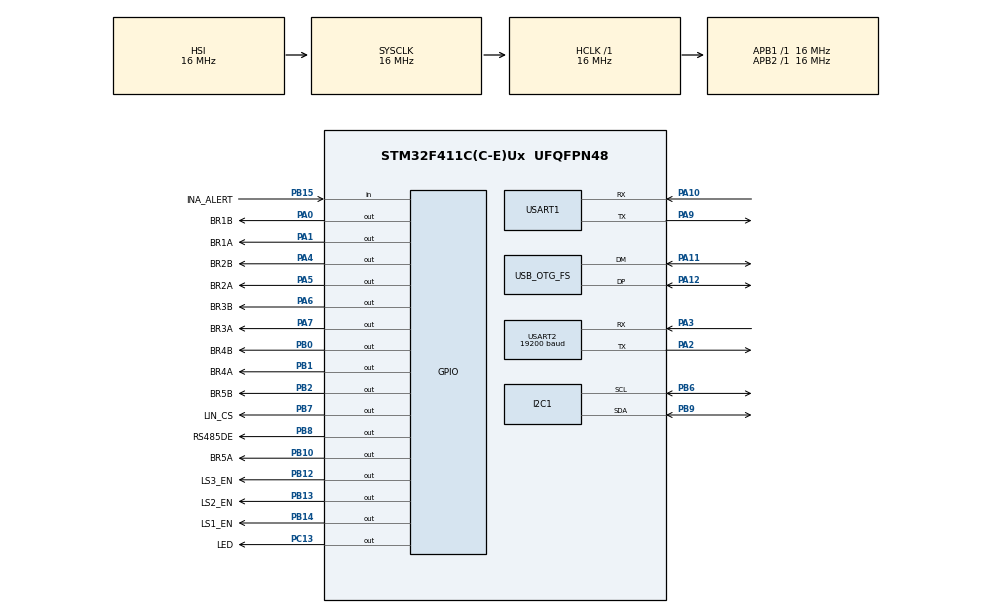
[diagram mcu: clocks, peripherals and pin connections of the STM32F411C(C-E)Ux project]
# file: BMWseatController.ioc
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Mcu.Family=STM32F4
Mcu.Name=STM32F411C(C-E)Ux
Mcu.Package=UFQFPN48
NVIC.OTG_FS_IRQn=true\:0\:0\:false\:false\:true\:false\:true\:true
NVIC.PriorityGroup=NVIC_PRIORITYGROUP_4
PA0-WKUP.GPIO_Label=BR1B
PA0-WKUP.Signal=GPIO_Output
PA1.GPIO_Label=BR1A
PA1.Signal=GPIO_Output
PA10.Mode=Asynchronous
PA10.Signal=USART1_RX
PA11.Mode=Device_Only
PA11.Signal=USB_OTG_FS_DM
PA12.Mode=Device_Only
PA12.Signal=USB_OTG_FS_DP
PA13.Mode=Serial_Wire
PA13.Signal=SYS_JTMS-SWDIO
PA14.Mode=Serial_Wire
PA14.Signal=SYS_JTCK-SWCLK
PA2.GPIO_Speed=GPIO_SPEED_FREQ_HIGH
PA2.Mode=LIN
PA2.Signal=USART2_TX
PA3.GPIO_PuPd=GPIO_PULLUP
PA3.GPIO_Speed=GPIO_SPEED_FREQ_HIGH
PA3.Mode=LIN
PA3.Signal=USART2_RX
PA4.GPIO_Label=BR2B
PA4.Signal=GPIO_Output
PA5.GPIO_Label=BR2A
PA5.Signal=GPIO_Output
PA6.GPIO_Label=BR3B
PA6.Signal=GPIO_Output
PA7.GPIO_Label=BR3A
PA7.Signal=GPIO_Output
PA9.Mode=Asynchronous
PA9.Signal=USART1_TX
PB0.GPIO_Label=BR4B
PB0.Signal=GPIO_Output
PB1.GPIO_Label=BR4A
PB1.Signal=GPIO_Output
PB10.GPIO_Label=BR5A
PB10.Signal=GPIO_Output
PB12.GPIO_Label=LS3_EN
PB12.Signal=GPIO_Output
PB13.GPIO_Label=LS2_EN
PB13.Signal=GPIO_Output
PB14.GPIO_Label=LS1_EN
PB14.Signal=GPIO_Output
PB15.GPIO_Label=INA_ALERT
PB15.GPIO_PuPd=GPIO_PULLUP
PB15.Signal=GPIO_Input
PB2.GPIO_Label=BR5B
PB2.Signal=GPIO_Output
PB6.Mode=I2C
PB6.Signal=I2C1_SCL
PB7.GPIO_Label=LIN_CS
PB7.Signal=GPIO_Output
PB8.GPIO_Label=RS485DE
PB8.Signal=GPIO_Output
PB9.Mode=I2C
PB9.Signal=I2C1_SDA
PC13-ANTI_TAMP.GPIO_Label=LED
PC13-ANTI_TAMP.Signal=GPIO_Output
PH0\ -\ OSC_IN.Mode=HSE-External-Oscillator
PH0\ -\ OSC_IN.Signal=RCC_OSC_IN
PH1\ -\ OSC_OUT.Mode=HSE-External-Oscillator
PH1\ -\ OSC_OUT.Signal=RCC_OSC_OUT
ProjectManager.HeapSize=0x200
ProjectManager.StackSize=0x400
ProjectManager.TargetToolchain=STM32CubeIDE
RCC.48MHZClocksFreq_Value=48000000
RCC.AHBFreq_Value=16000000
RCC.APB1Freq_Value=16000000
RCC.APB1TimFreq_Value=16000000
RCC.APB2Freq_Value=16000000
RCC.APB2TimFreq_Value=16000000
RCC.CortexFreq_Value=16000000
RCC.HCLKFreq_Value=16000000
RCC.HSE_VALUE=25000000
RCC.HSI_VALUE=16000000
RCC.LSE_VALUE=32768
RCC.PLLM=15
RCC.PLLN=144
RCC.PLLQ=5
RCC.SYSCLKFreq_VALUE=16000000
RCC.VCOOutputFreq_Value=240000000
USART1.VirtualMode=VM_ASYNC
USART2.BaudRate=19200
USART2.VirtualMode=VM_ASYNC
USB_DEVICE.CLASS_NAME_FS=CDC
USB_DEVICE.VirtualMode=Cdc
USB_DEVICE.VirtualModeFS=Cdc_FS
USB_OTG_FS.VirtualMode=Device_Only
VP_USB_DEVICE_VS_USB_DEVICE_CDC_FS.Mode=CDC_FS
board=custom

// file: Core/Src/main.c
/* USER CODE BEGIN Header */
/**
  ******************************************************************************
  * @file           : main.c
  * @brief          : Main program body
  ******************************************************************************
  * @attention
  *
  * Copyright (c) 2025 STMicroelectronics.
  * All rights reserved.
  *
  * This software is licensed under terms that can be found in the LICENSE file
  * in the root directory of this software component.
  * If no LICENSE file comes with this software, it is provided AS-IS.
  *
  ******************************************************************************
  */
/* USER CODE END Header */
#include "main.h"
#include "usb_device.h"

/* USER CODE BEGIN Includes */
#include "board.h"
#include "usbd_cdc_if.h"
#include "lin.h"
#include <string.h>
#include <stdio.h>
/* USER CODE END Includes */

/* USER CODE BEGIN PTD */
extern UART_HandleTypeDef huart2;   // USART2 from CubeMX (LIN mode)

/* USER CODE END PTD */

I2C_HandleTypeDef hi2c1;

UART_HandleTypeDef huart1;
UART_HandleTypeDef huart2;

/* USER CODE BEGIN PV */
uint8_t TxData[20];
/* USER CODE END PV */

void SystemClock_Config(void);
static void MX_GPIO_Init(void);
static void MX_I2C1_Init(void);
static void MX_USART1_UART_Init(void);
static void MX_USART2_UART_Init(void);

int main(void)
{

  /* MCU Configuration--------------------------------------------------------*/

  /* Reset of all peripherals, Initializes the Flash interface and the Systick. */
  HAL_Init();

  /* Configure the system clock */
  SystemClock_Config();

  /* Initialize all configured peripherals */
  MX_GPIO_Init();
  MX_I2C1_Init();
  MX_USART1_UART_Init();
  MX_USART2_UART_Init();
  MX_USB_DEVICE_Init();
  /* USER CODE BEGIN 2 */

  HAL_Delay(1000);
  HAL_GPIO_WritePin(LIN_CS_GPIO_Port, LIN_CS_Pin, GPIO_PIN_SET); //set LIN txcvr CS pin high
  const char *msg = "Hello BMW\r\n";

  /* USER CODE END 2 */

  /* Infinite loop */
  /* USER CODE BEGIN WHILE */
  while (1)
  {
	  Board_ReadLinAndDrive();
	  HAL_Delay(50);
//	  for (HalfBridge_t hb = HB1; hb <= HB5; hb++) {
//	      SetHalfBridge(hb, DIR_FORWARD);
//	      HAL_GPIO_TogglePin(LED_GPIO_Port, LED_Pin);
//	      HAL_Delay(3000);  // 3 seconds forward
//	      HAL_GPIO_TogglePin(LED_GPIO_Port, LED_Pin);
//
//	      SetHalfBridge(hb, DIR_REVERSE);
//	      HAL_GPIO_TogglePin(LED_GPIO_Port, LED_Pin);
//	      HAL_Delay(3000);  // 3 seconds reverse
//	      HAL_GPIO_TogglePin(LED_GPIO_Port, LED_Pin);
//	      SetHalfBridge(hb, DIR_IDLE);  // Optional step before idle all
//	      HAL_Delay(1000);  // Pause 1 second
//	      HAL_GPIO_TogglePin(LED_GPIO_Port, LED_Pin);
//
//	      SetHalfBridge(IDLE_MOTOR, DIR_IDLE);  // All off
//	      HAL_GPIO_TogglePin(LED_GPIO_Port, LED_Pin);
//	    }
    /* USER CODE END WHILE */

  }
}

void SystemClock_Config(void)
{
  RCC_OscInitTypeDef RCC_OscInitStruct = {0};
  RCC_ClkInitTypeDef RCC_ClkInitStruct = {0};

  /** Configure the main internal regulator output voltage
  */
  __HAL_RCC_PWR_CLK_ENABLE();
  __HAL_PWR_VOLTAGESCALING_CONFIG(PWR_REGULATOR_VOLTAGE_SCALE1);

  /** Initializes the RCC Oscillators according to the specified parameters
  * in the RCC_OscInitTypeDef structure.
  */
  RCC_OscInitStruct.OscillatorType = RCC_OSCILLATORTYPE_HSI|RCC_OSCILLATORTYPE_HSE;
  RCC_OscInitStruct.HSEState = RCC_HSE_ON;
  RCC_OscInitStruct.HSIState = RCC_HSI_ON;
  RCC_OscInitStruct.HSICalibrationValue = RCC_HSICALIBRATION_DEFAULT;
  RCC_OscInitStruct.PLL.PLLState = RCC_PLL_ON;
  RCC_OscInitStruct.PLL.PLLSource = RCC_PLLSOURCE_HSE;
  RCC_OscInitStruct.PLL.PLLM = 15;
  RCC_OscInitStruct.PLL.PLLN = 144;
  RCC_OscInitStruct.PLL.PLLP = RCC_PLLP_DIV2;
  RCC_OscInitStruct.PLL.PLLQ = 5;
  if (HAL_RCC_OscConfig(&RCC_OscInitStruct) != HAL_OK)
  {
    Error_Handler();
  }

  /** Initializes the CPU, AHB and APB buses clocks
  */
  RCC_ClkInitStruct.ClockType = RCC_CLOCKTYPE_HCLK|RCC_CLOCKTYPE_SYSCLK
                              |RCC_CLOCKTYPE_PCLK1|RCC_CLOCKTYPE_PCLK2;
  RCC_ClkInitStruct.SYSCLKSource = RCC_SYSCLKSOURCE_HSI;
  RCC_ClkInitStruct.AHBCLKDivider = RCC_SYSCLK_DIV1;
  RCC_ClkInitStruct.APB1CLKDivider = RCC_HCLK_DIV1;
  RCC_ClkInitStruct.APB2CLKDivider = RCC_HCLK_DIV1;

  if (HAL_RCC_ClockConfig(&RCC_ClkInitStruct, FLASH_LATENCY_0) != HAL_OK)
  {
    Error_Handler();
  }
}

static void MX_I2C1_Init(void)
{

  hi2c1.Instance = I2C1;
  hi2c1.Init.ClockSpeed = 100000;
  hi2c1.Init.DutyCycle = I2C_DUTYCYCLE_2;
  hi2c1.Init.OwnAddress1 = 0;
  hi2c1.Init.AddressingMode = I2C_ADDRESSINGMODE_7BIT;
  hi2c1.Init.DualAddressMode = I2C_DUALADDRESS_DISABLE;
  hi2c1.Init.OwnAddress2 = 0;
  hi2c1.Init.GeneralCallMode = I2C_GENERALCALL_DISABLE;
  hi2c1.Init.NoStretchMode = I2C_NOSTRETCH_DISABLE;
  if (HAL_I2C_Init(&hi2c1) != HAL_OK)
  {
    Error_Handler();
  }

}

static void MX_USART1_UART_Init(void)
{

  huart1.Instance = USART1;
  huart1.Init.BaudRate = 115200;
  huart1.Init.WordLength = UART_WORDLENGTH_8B;
  huart1.Init.StopBits = UART_STOPBITS_1;
  huart1.Init.Parity = UART_PARITY_NONE;
  huart1.Init.Mode = UART_MODE_TX_RX;
  huart1.Init.HwFlowCtl = UART_HWCONTROL_NONE;
  huart1.Init.OverSampling = UART_OVERSAMPLING_16;
  if (HAL_UART_Init(&huart1) != HAL_OK)
  {
    Error_Handler();
  }

}

static void MX_USART2_UART_Init(void)
{

  huart2.Instance = USART2;
  huart2.Init.BaudRate = 19200;
  huart2.Init.WordLength = UART_WORDLENGTH_8B;
  huart2.Init.StopBits = UART_STOPBITS_1;
  huart2.Init.Parity = UART_PARITY_NONE;
  huart2.Init.Mode = UART_MODE_TX_RX;
  huart2.Init.HwFlowCtl = UART_HWCONTROL_NONE;
  huart2.Init.OverSampling = UART_OVERSAMPLING_16;
  if (HAL_LIN_Init(&huart2, UART_LINBREAKDETECTLENGTH_11B) != HAL_OK)
  {
    Error_Handler();
  }

}

static void MX_GPIO_Init(void)
{
  GPIO_InitTypeDef GPIO_InitStruct = {0};

  /* GPIO Ports Clock Enable */
  __HAL_RCC_GPIOC_CLK_ENABLE();
  __HAL_RCC_GPIOH_CLK_ENABLE();
  __HAL_RCC_GPIOA_CLK_ENABLE();
  __HAL_RCC_GPIOB_CLK_ENABLE();

  /*Configure GPIO pin Output Level */
  HAL_GPIO_WritePin(LED_GPIO_Port, LED_Pin, GPIO_PIN_RESET);

  /*Configure GPIO pin Output Level */
  HAL_GPIO_WritePin(GPIOA, BR1B_Pin|BR1A_Pin|BR2B_Pin|BR2A_Pin
                          |BR3B_Pin|BR3A_Pin, GPIO_PIN_RESET);

  /*Configure GPIO pin Output Level */
  HAL_GPIO_WritePin(GPIOB, BR4B_Pin|BR4A_Pin|BR5B_Pin|BR5A_Pin
                          |LS3_EN_Pin|LS2_EN_Pin|LS1_EN_Pin|LIN_CS_Pin
                          |RS485DE_Pin, GPIO_PIN_RESET);

  /*Configure GPIO pin : LED_Pin */
  GPIO_InitStruct.Pin = LED_Pin;
  GPIO_InitStruct.Mode = GPIO_MODE_OUTPUT_PP;
  GPIO_InitStruct.Pull = GPIO_NOPULL;
  GPIO_InitStruct.Speed = GPIO_SPEED_FREQ_LOW;
  HAL_GPIO_Init(LED_GPIO_Port, &GPIO_InitStruct);

  /*Configure GPIO pins : BR1B_Pin BR1A_Pin BR2B_Pin BR2A_Pin
                           BR3B_Pin BR3A_Pin */
  GPIO_InitStruct.Pin = BR1B_Pin|BR1A_Pin|BR2B_Pin|BR2A_Pin
                          |BR3B_Pin|BR3A_Pin;
  GPIO_InitStruct.Mode = GPIO_MODE_OUTPUT_PP;
  GPIO_InitStruct.Pull = GPIO_NOPULL;
  GPIO_InitStruct.Speed = GPIO_SPEED_FREQ_LOW;
  HAL_GPIO_Init(GPIOA, &GPIO_InitStruct);

  /*Configure GPIO pins : BR4B_Pin BR4A_Pin BR5B_Pin BR5A_Pin
                           LS3_EN_Pin LS2_EN_Pin LS1_EN_Pin LIN_CS_Pin
                           RS485DE_Pin */
  GPIO_InitStruct.Pin = BR4B_Pin|BR4A_Pin|BR5B_Pin|BR5A_Pin
                          |LS3_EN_Pin|LS2_EN_Pin|LS1_EN_Pin|LIN_CS_Pin
                          |RS485DE_Pin;
  GPIO_InitStruct.Mode = GPIO_MODE_OUTPUT_PP;
  GPIO_InitStruct.Pull = GPIO_NOPULL;
  GPIO_InitStruct.Speed = GPIO_SPEED_FREQ_LOW;
  HAL_GPIO_Init(GPIOB, &GPIO_InitStruct);

  /*Configure GPIO pin : INA_ALERT_Pin */
  GPIO_InitStruct.Pin = INA_ALERT_Pin;
  GPIO_InitStruct.Mode = GPIO_MODE_INPUT;
  GPIO_InitStruct.Pull = GPIO_PULLUP;
  HAL_GPIO_Init(INA_ALERT_GPIO_Port, &GPIO_InitStruct);

}

void Error_Handler(void)
{
  __disable_irq();
  while (1)
  {
  }
}
